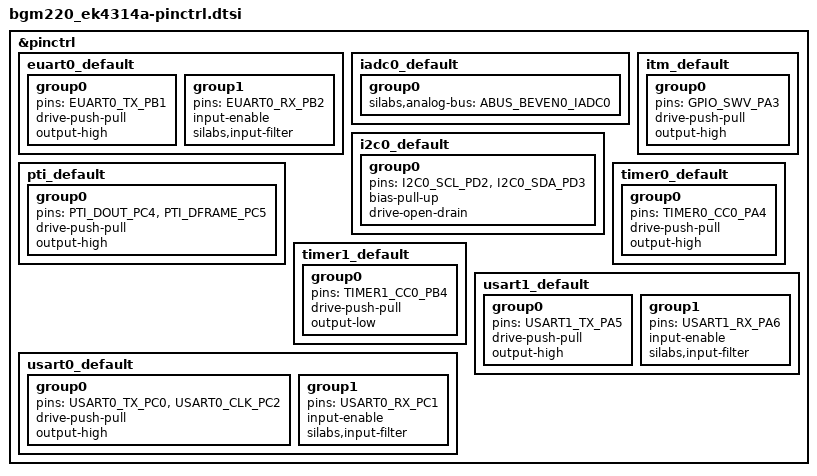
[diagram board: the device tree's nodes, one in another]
/*
 * Copyright The Zephyr Project Contributors
 *
 * SPDX-License-Identifier: Apache-2.0
 */

#include <dt-bindings/pinctrl/silabs/xg22-pinctrl.h>

&pinctrl {
	euart0_default: euart0_default {
		group0 {
			pins = <EUART0_TX_PB1>;
			drive-push-pull;
			output-high;
		};

		group1 {
			pins = <EUART0_RX_PB2>;
			input-enable;
			silabs,input-filter;
		};
	};

	iadc0_default: iadc0_default {
		group0 {
			silabs,analog-bus = <ABUS_BEVEN0_IADC0>;
		};
	};

	itm_default: itm_default {
		group0 {
			pins = <GPIO_SWV_PA3>;
			drive-push-pull;
			output-high;
		};
	};

	i2c0_default: i2c0_default {
		group0 {
			pins = <I2C0_SCL_PD2>, <I2C0_SDA_PD3>;
			bias-pull-up;
			drive-open-drain;
		};
	};

	pti_default: pti_default {
		group0 {
			pins = <PTI_DOUT_PC4>, <PTI_DFRAME_PC5>;
			drive-push-pull;
			output-high;
		};
	};

	timer0_default: timer0_default {
		group0 {
			pins = <TIMER0_CC0_PA4>;
			drive-push-pull;
			output-high;
		};
	};

	timer1_default: timer1_default {
		group0 {
			pins = <TIMER1_CC0_PB4>;
			drive-push-pull;
			output-low;
		};
	};

	usart0_default: usart0_default {
		group0 {
			pins = <USART0_TX_PC0>, <USART0_CLK_PC2>;
			drive-push-pull;
			output-high;
		};

		group1 {
			pins = <USART0_RX_PC1>;
			input-enable;
			silabs,input-filter;
		};
	};

	usart1_default: usart1_default {
		group0 {
			pins = <USART1_TX_PA5>;
			drive-push-pull;
			output-high;
		};

		group1 {
			pins = <USART1_RX_PA6>;
			input-enable;
			silabs,input-filter;
		};
	};
};
